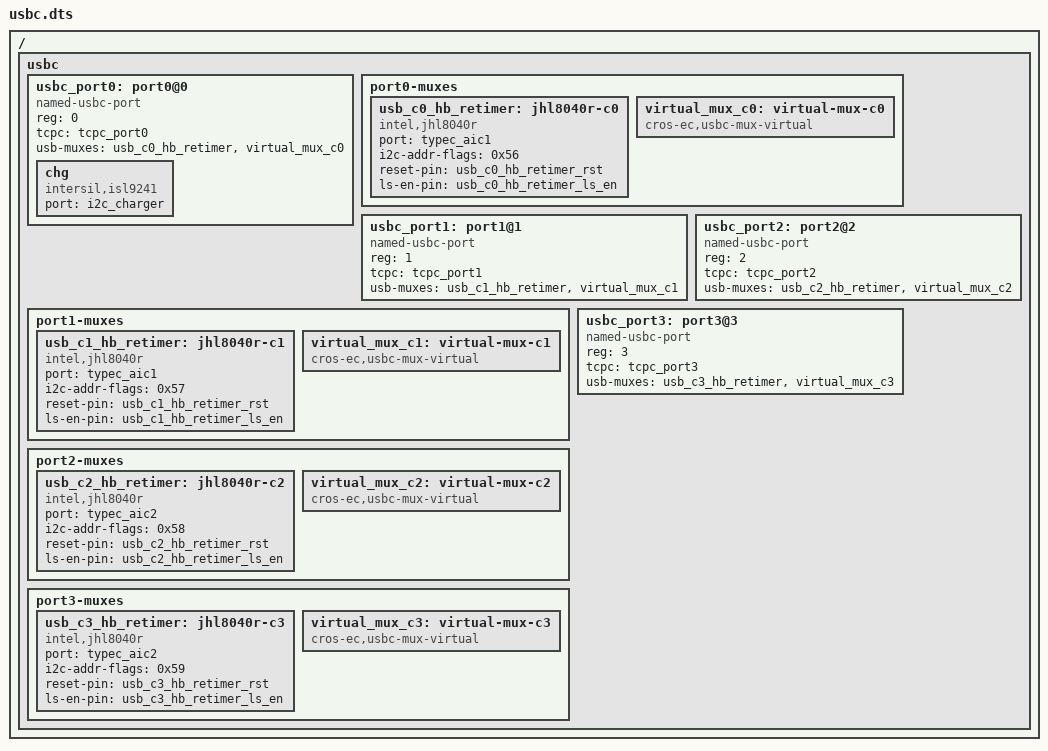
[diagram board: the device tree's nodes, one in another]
/* Copyright 2022 The Chromium OS Authors. All rights reserved.
 * Use of this source code is governed by a BSD-style license that can be
 * found in the LICENSE file.
 */

/ {
	usbc {
		#address-cells = <1>;
		#size-cells = <0>;

		usbc_port0: port0@0 {
			compatible = "named-usbc-port";
			reg = <0>;
			tcpc = <&tcpc_port0>;
			chg {
				compatible = "intersil,isl9241";
				status = "okay";
				port = <&i2c_charger>;
			};
			usb-muxes = <&usb_c0_hb_retimer &virtual_mux_c0>;
		};
		port0-muxes {
			usb_c0_hb_retimer: jhl8040r-c0 {
				compatible = "intel,jhl8040r";
				port = <&typec_aic1>;
				i2c-addr-flags = <0x56>;
				reset-pin = <&usb_c0_hb_retimer_rst>;
				ls-en-pin = <&usb_c0_hb_retimer_ls_en>;
			};
			virtual_mux_c0: virtual-mux-c0 {
				compatible = "cros-ec,usbc-mux-virtual";
			};
		};

		usbc_port1: port1@1 {
			compatible = "named-usbc-port";
			reg = <1>;
			tcpc = <&tcpc_port1>;
			usb-muxes = <&usb_c1_hb_retimer &virtual_mux_c1>;
		};
		port1-muxes {
			usb_c1_hb_retimer: jhl8040r-c1 {
				compatible = "intel,jhl8040r";
				port = <&typec_aic1>;
				i2c-addr-flags = <0x57>;
				reset-pin = <&usb_c1_hb_retimer_rst>;
				ls-en-pin = <&usb_c1_hb_retimer_ls_en>;
			};
			virtual_mux_c1: virtual-mux-c1 {
				compatible = "cros-ec,usbc-mux-virtual";
			};
		};

		usbc_port2: port2@2 {
			compatible = "named-usbc-port";
			reg = <2>;
			tcpc = <&tcpc_port2>;
			usb-muxes = <&usb_c2_hb_retimer &virtual_mux_c2>;
		};
		port2-muxes {
			usb_c2_hb_retimer: jhl8040r-c2 {
				compatible = "intel,jhl8040r";
				port = <&typec_aic2>;
				i2c-addr-flags = <0x58>;
				reset-pin = <&usb_c2_hb_retimer_rst>;
				ls-en-pin = <&usb_c2_hb_retimer_ls_en>;
			};
			virtual_mux_c2: virtual-mux-c2 {
				compatible = "cros-ec,usbc-mux-virtual";
			};
		};

		usbc_port3: port3@3 {
			compatible = "named-usbc-port";
			reg = <3>;
			tcpc = <&tcpc_port3>;
			usb-muxes = <&usb_c3_hb_retimer &virtual_mux_c3>;
		};
		port3-muxes {
			usb_c3_hb_retimer: jhl8040r-c3 {
				compatible = "intel,jhl8040r";
				port = <&typec_aic2>;
				i2c-addr-flags = <0x59>;
				reset-pin = <&usb_c3_hb_retimer_rst>;
				ls-en-pin = <&usb_c3_hb_retimer_ls_en>;
			};
			virtual_mux_c3: virtual-mux-c3 {
				compatible = "cros-ec,usbc-mux-virtual";
			};
		};
	};
};
